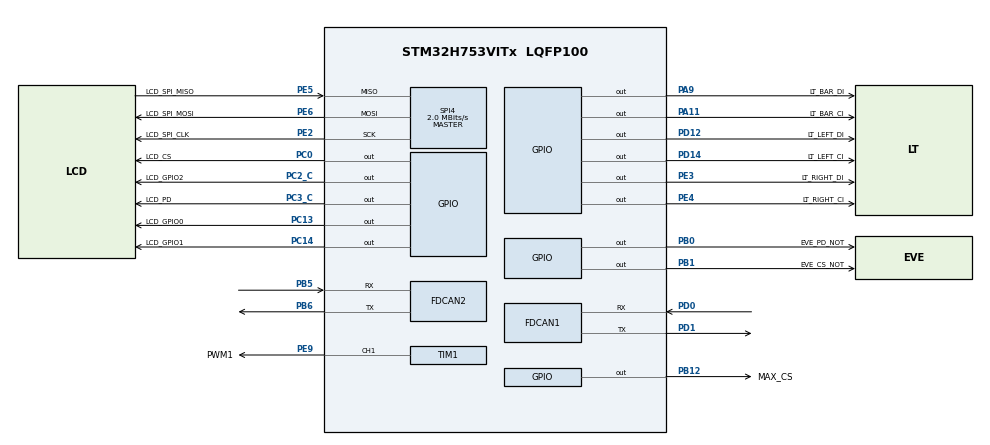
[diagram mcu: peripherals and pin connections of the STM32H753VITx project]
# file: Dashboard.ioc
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CORTEX_M7.default_mode_Activation=1
FDCAN1.CalculateBaudRateNominal=500000
FDCAN1.CalculateTimeBitNominal=2000
FDCAN1.CalculateTimeQuantumNominal=125.0
FDCAN1.NominalPrescaler=1
FDCAN1.NominalTimeSeg1=13
FDCAN1.NominalTimeSeg2=2
FDCAN1.StdFiltersNbr=16
FDCAN2.CalculateBaudRateNominal=1000000
FDCAN2.CalculateTimeBitNominal=1000
FDCAN2.CalculateTimeQuantumNominal=125.0
FDCAN2.NominalPrescaler=1
FDCAN2.NominalTimeSeg1=6
FDCAN2.NominalTimeSeg2=1
FDCAN2.RxFifo0ElmtsNbr=8
FDCAN2.StdFiltersNbr=14
FDCAN2.TxFifoQueueElmtsNbr=3
Mcu.Family=STM32H7
Mcu.Name=STM32H753VITx
Mcu.Package=LQFP100
NVIC.PriorityGroup=NVIC_PRIORITYGROUP_4
PA11.GPIO_Label=LT_BAR_CI
PA11.Signal=GPIO_Output
PA13\ (JTMS/SWDIO).Mode=JTAG_5_pins
PA13\ (JTMS/SWDIO).Signal=DEBUG_JTMS-SWDIO
PA14\ (JTCK/SWCLK).Mode=JTAG_5_pins
PA14\ (JTCK/SWCLK).Signal=DEBUG_JTCK-SWCLK
PA15\ (JTDI).Mode=JTAG_5_pins
PA15\ (JTDI).Signal=DEBUG_JTDI
PA9.GPIO_Label=LT_BAR_DI
PA9.Signal=GPIO_Output
PB0.GPIO_Label=EVE_PD_NOT
PB0.Signal=GPIO_Output
PB1.GPIO_Label=EVE_CS_NOT
PB1.Signal=GPIO_Output
PB12.GPIO_Label=MAX_CS
PB12.Signal=GPIO_Output
PB3\ (JTDO/TRACESWO).Mode=JTAG_5_pins
PB3\ (JTDO/TRACESWO).Signal=DEBUG_JTDO-SWO
PB4\ (NJTRST).Mode=JTAG_5_pins
PB4\ (NJTRST).Signal=DEBUG_JTRST
PB5.Mode=FDCAN_Activate
PB5.Signal=FDCAN2_RX
PB6.Mode=FDCAN_Activate
PB6.Signal=FDCAN2_TX
PC0.GPIO_Label=LCD_CS
PC0.Signal=GPIO_Output
PC13.GPIO_Label=LCD_GPIO0
PC13.Signal=GPIO_Output
PC14-OSC32_IN\ (OSC32_IN).GPIO_Label=LCD_GPIO1
PC14-OSC32_IN\ (OSC32_IN).Signal=GPIO_Output
PC2_C.GPIO_Label=LCD_GPIO2
PC2_C.Signal=GPIO_Output
PC3_C.GPIO_Label=LCD_PD
PC3_C.Signal=GPIO_Output
PD0.Mode=FDCAN_Activate
PD0.Signal=FDCAN1_RX
PD1.Mode=FDCAN_Activate
PD1.Signal=FDCAN1_TX
PD12.GPIO_Label=LT_LEFT_DI
PD12.Signal=GPIO_Output
PD14.GPIO_Label=LT_LEFT_CI
PD14.Signal=GPIO_Output
PE2.GPIO_Label=LCD_SPI_CLK
PE2.Mode=Full_Duplex_Master
PE2.Signal=SPI4_SCK
PE3.GPIO_Label=LT_RIGHT_DI
PE3.Signal=GPIO_Output
PE4.GPIO_Label=LT_RIGHT_CI
PE4.Signal=GPIO_Output
PE5.GPIO_Label=LCD_SPI_MISO
PE5.Mode=Full_Duplex_Master
PE5.Signal=SPI4_MISO
PE6.GPIO_Label=LCD_SPI_MOSI
PE6.Mode=Full_Duplex_Master
PE6.Signal=SPI4_MOSI
PE9.GPIO_Label=PWM1
PE9.Signal=S_TIM1_CH1
PH0-OSC_IN\ (PH0).Mode=HSE-External-Oscillator
PH0-OSC_IN\ (PH0).Signal=RCC_OSC_IN
PH1-OSC_OUT\ (PH1).Mode=HSE-External-Oscillator
PH1-OSC_OUT\ (PH1).Signal=RCC_OSC_OUT
ProjectManager.HeapSize=0x200
ProjectManager.StackSize=0x400
ProjectManager.TargetToolchain=STM32CubeIDE
RCC.ADCFreq_Value=129000000
RCC.APB1Freq_Value=8000000
RCC.APB2Freq_Value=4000000
RCC.APB3Freq_Value=8000000
RCC.APB4Freq_Value=8000000
RCC.CortexFreq_Value=8000000
RCC.D2PPRE2=RCC_APB2_DIV2
RCC.DIVM1=4
RCC.DIVN1=10
RCC.DIVQ1=3
RCC.FDCANCLockSelection=RCC_FDCANCLKSOURCE_HSE
RCC.HCLKFreq_Value=8000000
RCC.HSE_VALUE=8000000
RCC.PLLFRACN=0
RCC.SYSCLKFreq_VALUE=8000000
RCC.SYSCLKSource=RCC_SYSCLKSOURCE_HSE
RCC.USBFreq_Value=53333333.333333336
SH.S_TIM1_CH1.0=TIM1_CH1,PWM Generation1 CH1
SPI4.CalculateBaudRate=2.0 MBits/s
SPI4.DataSize=SPI_DATASIZE_8BIT
SPI4.Direction=SPI_DIRECTION_2LINES
SPI4.Mode=SPI_MODE_MASTER
SPI4.VirtualType=VM_MASTER
TIM1.Channel-PWM\ Generation1\ CH1=TIM_CHANNEL_1
VP_MEMORYMAP_VS_MEMORYMAP.Mode=CurAppReg
VP_TIM1_VS_OPM.Mode=OPM_bit
board=custom

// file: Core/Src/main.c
/* USER CODE BEGIN Header */
/**
  ******************************************************************************
  * @file           : main.c
  * @brief          : Main program body
  ******************************************************************************
  * @attention
  *
  * Copyright (c) 2025 STMicroelectronics.
  * All rights reserved.
  *
  * This software is licensed under terms that can be found in the LICENSE file
  * in the root directory of this software component.
  * If no LICENSE file comes with this software, it is provided AS-IS.
  *
  ******************************************************************************
  */
/* USER CODE END Header */
#include "main.h"

/* USER CODE BEGIN Includes */
#include "lcd.h"
#include <stdio.h>
/* USER CODE END Includes */

FDCAN_HandleTypeDef hfdcan1;
FDCAN_HandleTypeDef hfdcan2;

SPI_HandleTypeDef hspi4;

TIM_HandleTypeDef htim1;

void SystemClock_Config(void);
static void MPU_Config(void);
static void MX_GPIO_Init(void);
static void MX_FDCAN1_Init(void);
static void MX_FDCAN2_Init(void);
static void MX_SPI4_Init(void);
static void MX_TIM1_Init(void);

int main(void)
{

  /* MPU Configuration--------------------------------------------------------*/
  MPU_Config();

  /* MCU Configuration--------------------------------------------------------*/

  /* Reset of all peripherals, Initializes the Flash interface and the Systick. */
  HAL_Init();

  /* Configure the system clock */
  SystemClock_Config();

  /* Initialize all configured peripherals */
  MX_GPIO_Init();
  MX_FDCAN1_Init();
  MX_FDCAN2_Init();
  MX_SPI4_Init();
  MX_TIM1_Init();
  /* USER CODE BEGIN 2 */
  //static_assert(sizeof(HAL_StatusTypeDef) > 0, "HAL_StatusTypeDef missing");
  extern void app_main();
  app_main();
  //LCD_init();
  /* USER CODE END 2 */

  /* Infinite loop */
  while (1)
  {

  }
}

void SystemClock_Config(void)
{
  RCC_OscInitTypeDef RCC_OscInitStruct = {0};
  RCC_ClkInitTypeDef RCC_ClkInitStruct = {0};

  /** Supply configuration update enable
  */
  HAL_PWREx_ConfigSupply(PWR_LDO_SUPPLY);

  /** Configure the main internal regulator output voltage
  */
  __HAL_PWR_VOLTAGESCALING_CONFIG(PWR_REGULATOR_VOLTAGE_SCALE3);

  while(!__HAL_PWR_GET_FLAG(PWR_FLAG_VOSRDY)) {}

  /** Initializes the RCC Oscillators according to the specified parameters
  * in the RCC_OscInitTypeDef structure.
  */
  RCC_OscInitStruct.OscillatorType = RCC_OSCILLATORTYPE_HSE;
  RCC_OscInitStruct.HSEState = RCC_HSE_ON;
  RCC_OscInitStruct.PLL.PLLState = RCC_PLL_NONE;
  if (HAL_RCC_OscConfig(&RCC_OscInitStruct) != HAL_OK)
  {
    Error_Handler();
  }

  /** Initializes the CPU, AHB and APB buses clocks
  */
  RCC_ClkInitStruct.ClockType = RCC_CLOCKTYPE_HCLK|RCC_CLOCKTYPE_SYSCLK
                              |RCC_CLOCKTYPE_PCLK1|RCC_CLOCKTYPE_PCLK2
                              |RCC_CLOCKTYPE_D3PCLK1|RCC_CLOCKTYPE_D1PCLK1;
  RCC_ClkInitStruct.SYSCLKSource = RCC_SYSCLKSOURCE_HSE;
  RCC_ClkInitStruct.SYSCLKDivider = RCC_SYSCLK_DIV1;
  RCC_ClkInitStruct.AHBCLKDivider = RCC_HCLK_DIV1;
  RCC_ClkInitStruct.APB3CLKDivider = RCC_APB3_DIV1;
  RCC_ClkInitStruct.APB1CLKDivider = RCC_APB1_DIV1;
  RCC_ClkInitStruct.APB2CLKDivider = RCC_APB2_DIV2;
  RCC_ClkInitStruct.APB4CLKDivider = RCC_APB4_DIV1;

  if (HAL_RCC_ClockConfig(&RCC_ClkInitStruct, FLASH_LATENCY_0) != HAL_OK)
  {
    Error_Handler();
  }
}

static void MX_FDCAN1_Init(void)
{

  hfdcan1.Instance = FDCAN1;
  hfdcan1.Init.FrameFormat = FDCAN_FRAME_CLASSIC;
  hfdcan1.Init.Mode = FDCAN_MODE_NORMAL;
  hfdcan1.Init.AutoRetransmission = DISABLE;
  hfdcan1.Init.TransmitPause = DISABLE;
  hfdcan1.Init.ProtocolException = DISABLE;
  // FDCAN1 carries VCU at 500 kbit/s
  hfdcan1.Init.NominalPrescaler = 1;
  hfdcan1.Init.NominalSyncJumpWidth = 1;
  hfdcan1.Init.NominalTimeSeg1 = 13;
  hfdcan1.Init.NominalTimeSeg2 = 2;
  hfdcan1.Init.DataPrescaler = 1;
  hfdcan1.Init.DataSyncJumpWidth = 1;
  hfdcan1.Init.DataTimeSeg1 = 1;
  hfdcan1.Init.DataTimeSeg2 = 1;
  hfdcan1.Init.MessageRAMOffset = 64;   // placed AFTER FDCAN2's region in shared SRAMCAN
  hfdcan1.Init.StdFiltersNbr = 16;
  hfdcan1.Init.ExtFiltersNbr = 0;
  hfdcan1.Init.RxFifo0ElmtsNbr = 8;
  hfdcan1.Init.RxFifo0ElmtSize = FDCAN_DATA_BYTES_8;
  hfdcan1.Init.RxFifo1ElmtsNbr = 0;
  hfdcan1.Init.RxFifo1ElmtSize = FDCAN_DATA_BYTES_8;
  hfdcan1.Init.RxBuffersNbr = 0;
  hfdcan1.Init.RxBufferSize = FDCAN_DATA_BYTES_8;
  hfdcan1.Init.TxEventsNbr = 0;
  hfdcan1.Init.TxBuffersNbr = 0;
  hfdcan1.Init.TxFifoQueueElmtsNbr = 3;
  hfdcan1.Init.TxFifoQueueMode = FDCAN_TX_FIFO_OPERATION;
  hfdcan1.Init.TxElmtSize = FDCAN_DATA_BYTES_8;
  if (HAL_FDCAN_Init(&hfdcan1) != HAL_OK)
  {
    Error_Handler();
  }

}

static void MX_FDCAN2_Init(void)
{

  hfdcan2.Instance = FDCAN2;
  hfdcan2.Init.FrameFormat = FDCAN_FRAME_CLASSIC;
  hfdcan2.Init.Mode = FDCAN_MODE_NORMAL;
  hfdcan2.Init.AutoRetransmission = DISABLE;
  hfdcan2.Init.TransmitPause = DISABLE;
  hfdcan2.Init.ProtocolException = DISABLE;
  // FDCAN2 carries BMS at 1 Mbit/s
  hfdcan2.Init.NominalPrescaler = 1;
  hfdcan2.Init.NominalSyncJumpWidth = 1;
  hfdcan2.Init.NominalTimeSeg1 = 6;
  hfdcan2.Init.NominalTimeSeg2 = 1;
  hfdcan2.Init.DataPrescaler = 1;
  hfdcan2.Init.DataSyncJumpWidth = 1;
  hfdcan2.Init.DataTimeSeg1 = 1;
  hfdcan2.Init.DataTimeSeg2 = 1;
  hfdcan2.Init.MessageRAMOffset = 0;
  hfdcan2.Init.StdFiltersNbr = 14;
  hfdcan2.Init.ExtFiltersNbr = 0;
  hfdcan2.Init.RxFifo0ElmtsNbr = 8;
  hfdcan2.Init.RxFifo0ElmtSize = FDCAN_DATA_BYTES_8;
  hfdcan2.Init.RxFifo1ElmtsNbr = 0;
  hfdcan2.Init.RxFifo1ElmtSize = FDCAN_DATA_BYTES_8;
  hfdcan2.Init.RxBuffersNbr = 0;
  hfdcan2.Init.RxBufferSize = FDCAN_DATA_BYTES_8;
  hfdcan2.Init.TxEventsNbr = 0;
  hfdcan2.Init.TxBuffersNbr = 0;
  hfdcan2.Init.TxFifoQueueElmtsNbr = 3;
  hfdcan2.Init.TxFifoQueueMode = FDCAN_TX_FIFO_OPERATION;
  hfdcan2.Init.TxElmtSize = FDCAN_DATA_BYTES_8;
  if (HAL_FDCAN_Init(&hfdcan2) != HAL_OK)
  {
    Error_Handler();
  }

}

static void MX_SPI4_Init(void)
{

  /* SPI4 parameter configuration*/
  hspi4.Instance = SPI4;
  hspi4.Init.Mode = SPI_MODE_MASTER;
  hspi4.Init.Direction = SPI_DIRECTION_2LINES;
  hspi4.Init.DataSize = SPI_DATASIZE_8BIT;
  hspi4.Init.CLKPolarity = SPI_POLARITY_LOW;
  hspi4.Init.CLKPhase = SPI_PHASE_1EDGE;
  hspi4.Init.NSS = SPI_NSS_SOFT;
  hspi4.Init.BaudRatePrescaler = SPI_BAUDRATEPRESCALER_2;
  hspi4.Init.FirstBit = SPI_FIRSTBIT_MSB;
  hspi4.Init.TIMode = SPI_TIMODE_DISABLE;
  hspi4.Init.CRCCalculation = SPI_CRCCALCULATION_DISABLE;
  hspi4.Init.CRCPolynomial = 0x0;
  hspi4.Init.NSSPMode = SPI_NSS_PULSE_ENABLE;
  hspi4.Init.NSSPolarity = SPI_NSS_POLARITY_LOW;
  hspi4.Init.FifoThreshold = SPI_FIFO_THRESHOLD_01DATA;
  hspi4.Init.TxCRCInitializationPattern = SPI_CRC_INITIALIZATION_ALL_ZERO_PATTERN;
  hspi4.Init.RxCRCInitializationPattern = SPI_CRC_INITIALIZATION_ALL_ZERO_PATTERN;
  hspi4.Init.MasterSSIdleness = SPI_MASTER_SS_IDLENESS_00CYCLE;
  hspi4.Init.MasterInterDataIdleness = SPI_MASTER_INTERDATA_IDLENESS_00CYCLE;
  hspi4.Init.MasterReceiverAutoSusp = SPI_MASTER_RX_AUTOSUSP_DISABLE;
  hspi4.Init.MasterKeepIOState = SPI_MASTER_KEEP_IO_STATE_DISABLE;
  hspi4.Init.IOSwap = SPI_IO_SWAP_DISABLE;
  if (HAL_SPI_Init(&hspi4) != HAL_OK)
  {
    Error_Handler();
  }

}

static void MX_TIM1_Init(void)
{

  TIM_MasterConfigTypeDef sMasterConfig = {0};
  TIM_OC_InitTypeDef sConfigOC = {0};
  TIM_BreakDeadTimeConfigTypeDef sBreakDeadTimeConfig = {0};

  htim1.Instance = TIM1;
  htim1.Init.Prescaler = 0;
  htim1.Init.CounterMode = TIM_COUNTERMODE_UP;
  htim1.Init.Period = 65535;
  htim1.Init.ClockDivision = TIM_CLOCKDIVISION_DIV1;
  htim1.Init.RepetitionCounter = 0;
  htim1.Init.AutoReloadPreload = TIM_AUTORELOAD_PRELOAD_DISABLE;
  if (HAL_TIM_PWM_Init(&htim1) != HAL_OK)
  {
    Error_Handler();
  }
  if (HAL_TIM_OnePulse_Init(&htim1, TIM_OPMODE_SINGLE) != HAL_OK)
  {
    Error_Handler();
  }
  sMasterConfig.MasterOutputTrigger = TIM_TRGO_RESET;
  sMasterConfig.MasterOutputTrigger2 = TIM_TRGO2_RESET;
  sMasterConfig.MasterSlaveMode = TIM_MASTERSLAVEMODE_DISABLE;
  if (HAL_TIMEx_MasterConfigSynchronization(&htim1, &sMasterConfig) != HAL_OK)
  {
    Error_Handler();
  }
  sConfigOC.OCMode = TIM_OCMODE_PWM1;
  sConfigOC.Pulse = 0;
  sConfigOC.OCPolarity = TIM_OCPOLARITY_HIGH;
  sConfigOC.OCNPolarity = TIM_OCNPOLARITY_HIGH;
  sConfigOC.OCFastMode = TIM_OCFAST_DISABLE;
  sConfigOC.OCIdleState = TIM_OCIDLESTATE_RESET;
  sConfigOC.OCNIdleState = TIM_OCNIDLESTATE_RESET;
  if (HAL_TIM_PWM_ConfigChannel(&htim1, &sConfigOC, TIM_CHANNEL_1) != HAL_OK)
  {
    Error_Handler();
  }
  sBreakDeadTimeConfig.OffStateRunMode = TIM_OSSR_DISABLE;
  sBreakDeadTimeConfig.OffStateIDLEMode = TIM_OSSI_DISABLE;
  sBreakDeadTimeConfig.LockLevel = TIM_LOCKLEVEL_OFF;
  sBreakDeadTimeConfig.DeadTime = 0;
  sBreakDeadTimeConfig.BreakState = TIM_BREAK_DISABLE;
  sBreakDeadTimeConfig.BreakPolarity = TIM_BREAKPOLARITY_HIGH;
  sBreakDeadTimeConfig.BreakFilter = 0;
  sBreakDeadTimeConfig.Break2State = TIM_BREAK2_DISABLE;
  sBreakDeadTimeConfig.Break2Polarity = TIM_BREAK2POLARITY_HIGH;
  sBreakDeadTimeConfig.Break2Filter = 0;
  sBreakDeadTimeConfig.AutomaticOutput = TIM_AUTOMATICOUTPUT_DISABLE;
  if (HAL_TIMEx_ConfigBreakDeadTime(&htim1, &sBreakDeadTimeConfig) != HAL_OK)
  {
    Error_Handler();
  }
  HAL_TIM_MspPostInit(&htim1);

}

static void MX_GPIO_Init(void)
{
  GPIO_InitTypeDef GPIO_InitStruct = {0};

  /* GPIO Ports Clock Enable */
  __HAL_RCC_GPIOE_CLK_ENABLE();
  __HAL_RCC_GPIOC_CLK_ENABLE();
  __HAL_RCC_GPIOH_CLK_ENABLE();
  __HAL_RCC_GPIOB_CLK_ENABLE();
  __HAL_RCC_GPIOD_CLK_ENABLE();
  __HAL_RCC_GPIOA_CLK_ENABLE();

  /*Configure GPIO pin Output Level */
  HAL_GPIO_WritePin(GPIOE, LT_RIGHT_DI_Pin|LT_RIGHT_CI_Pin, GPIO_PIN_RESET);

  /*Configure GPIO pin Output Level */
  HAL_GPIO_WritePin(GPIOC, LCD_GPIO0_Pin|LCD_GPIO1_Pin|LCD_CS_Pin|LCD_GPIO2_Pin
                          |LCD_PD_Pin, GPIO_PIN_RESET);

  /*Configure GPIO pin Output Level */
  HAL_GPIO_WritePin(GPIOB, EVE_PD_NOT_Pin|EVE_CS_NOT_Pin|MAX_CS_Pin, GPIO_PIN_RESET);

  /*Configure GPIO pin Output Level */
  HAL_GPIO_WritePin(GPIOD, LT_LEFT_DI_Pin|LT_LEFT_CI_Pin, GPIO_PIN_RESET);

  /*Configure GPIO pin Output Level */
  HAL_GPIO_WritePin(GPIOA, LT_BAR_DI_Pin|LT_BAR_CI_Pin, GPIO_PIN_RESET);

  /*Configure GPIO pins : LT_RIGHT_DI_Pin LT_RIGHT_CI_Pin */
  GPIO_InitStruct.Pin = LT_RIGHT_DI_Pin|LT_RIGHT_CI_Pin;
  GPIO_InitStruct.Mode = GPIO_MODE_OUTPUT_PP;
  GPIO_InitStruct.Pull = GPIO_NOPULL;
  GPIO_InitStruct.Speed = GPIO_SPEED_FREQ_LOW;
  HAL_GPIO_Init(GPIOE, &GPIO_InitStruct);

  /*Configure GPIO pins : LCD_GPIO0_Pin LCD_GPIO1_Pin LCD_CS_Pin LCD_GPIO2_Pin
                           LCD_PD_Pin */
  GPIO_InitStruct.Pin = LCD_GPIO0_Pin|LCD_GPIO1_Pin|LCD_CS_Pin|LCD_GPIO2_Pin
                          |LCD_PD_Pin;
  GPIO_InitStruct.Mode = GPIO_MODE_OUTPUT_PP;
  GPIO_InitStruct.Pull = GPIO_NOPULL;
  GPIO_InitStruct.Speed = GPIO_SPEED_FREQ_LOW;
  HAL_GPIO_Init(GPIOC, &GPIO_InitStruct);

  /*Configure GPIO pins : EVE_PD_NOT_Pin EVE_CS_NOT_Pin MAX_CS_Pin */
  GPIO_InitStruct.Pin = EVE_PD_NOT_Pin|EVE_CS_NOT_Pin|MAX_CS_Pin;
  GPIO_InitStruct.Mode = GPIO_MODE_OUTPUT_PP;
  GPIO_InitStruct.Pull = GPIO_NOPULL;
  GPIO_InitStruct.Speed = GPIO_SPEED_FREQ_LOW;
  HAL_GPIO_Init(GPIOB, &GPIO_InitStruct);

  /*Configure GPIO pins : LT_LEFT_DI_Pin LT_LEFT_CI_Pin */
  GPIO_InitStruct.Pin = LT_LEFT_DI_Pin|LT_LEFT_CI_Pin;
  GPIO_InitStruct.Mode = GPIO_MODE_OUTPUT_PP;
  GPIO_InitStruct.Pull = GPIO_NOPULL;
  GPIO_InitStruct.Speed = GPIO_SPEED_FREQ_LOW;
  HAL_GPIO_Init(GPIOD, &GPIO_InitStruct);

  /*Configure GPIO pins : LT_BAR_DI_Pin LT_BAR_CI_Pin */
  GPIO_InitStruct.Pin = LT_BAR_DI_Pin|LT_BAR_CI_Pin;
  GPIO_InitStruct.Mode = GPIO_MODE_OUTPUT_PP;
  GPIO_InitStruct.Pull = GPIO_NOPULL;
  GPIO_InitStruct.Speed = GPIO_SPEED_FREQ_LOW;
  HAL_GPIO_Init(GPIOA, &GPIO_InitStruct);

  /*AnalogSwitch Config */
  HAL_SYSCFG_AnalogSwitchConfig(SYSCFG_SWITCH_PC2, SYSCFG_SWITCH_PC2_CLOSE);

  /*AnalogSwitch Config */
  HAL_SYSCFG_AnalogSwitchConfig(SYSCFG_SWITCH_PC3, SYSCFG_SWITCH_PC3_CLOSE);

}

 /* MPU Configuration */

void MPU_Config(void)
{
  MPU_Region_InitTypeDef MPU_InitStruct = {0};

  /* Disables the MPU */
  HAL_MPU_Disable();

  /** Initializes and configures the Region and the memory to be protected
  */
  MPU_InitStruct.Enable = MPU_REGION_ENABLE;
  MPU_InitStruct.Number = MPU_REGION_NUMBER0;
  MPU_InitStruct.BaseAddress = 0x0;
  MPU_InitStruct.Size = MPU_REGION_SIZE_4GB;
  MPU_InitStruct.SubRegionDisable = 0x87;
  MPU_InitStruct.TypeExtField = MPU_TEX_LEVEL0;
  MPU_InitStruct.AccessPermission = MPU_REGION_NO_ACCESS;
  MPU_InitStruct.DisableExec = MPU_INSTRUCTION_ACCESS_DISABLE;
  MPU_InitStruct.IsShareable = MPU_ACCESS_SHAREABLE;
  MPU_InitStruct.IsCacheable = MPU_ACCESS_NOT_CACHEABLE;
  MPU_InitStruct.IsBufferable = MPU_ACCESS_NOT_BUFFERABLE;

  HAL_MPU_ConfigRegion(&MPU_InitStruct);
  /* Enables the MPU */
  HAL_MPU_Enable(MPU_PRIVILEGED_DEFAULT);

}

void Error_Handler(void)
{
  /* USER CODE BEGIN Error_Handler_Debug */
  /* User can add his own implementation to report the HAL error return state */
  __disable_irq();
  while (1)
  {
	  printf("IN ERROR HANDLER");
  }
  /* USER CODE END Error_Handler_Debug */
}
